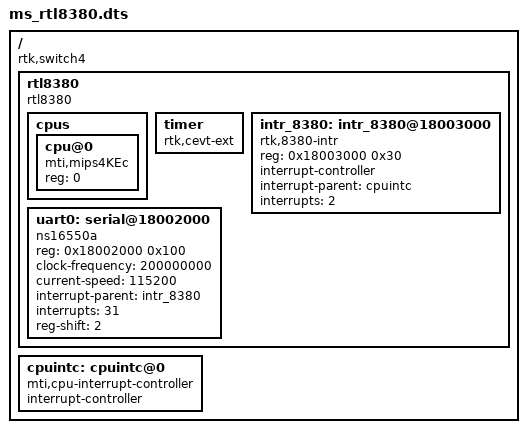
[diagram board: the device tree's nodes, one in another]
/*
 * Realtek Semiconductor Corp.
 *
 * Device Tree Structure
 *
 * RTK Management Switch
 */

/dts-v1/;

#include <dt-bindings/interrupt-controller/mips-gic.h>
#include <dt-bindings/interrupt-controller/irq.h>
#include "../chipDrv/rtl838x/rtk_bsp_rtl8380_intr.h"

/ {
    compatible = "rtk,switch4";
    #address-cells = <1>;
    #size-cells = <1>;

    rtl8380 {
        compatible = "rtl8380", "simple-bus";
        #address-cells = <1>;
        #size-cells = <1>;
        ranges;

        cpus {
            #address-cells = <1>;
            #size-cells = <0>;

            cpu@0 {
                compatible = "mti,mips4KEc";
                device_type = "cpu";
                reg = <0>;
            };
        };

        timer {
            compatible = "rtk,cevt-ext";
        };

        intr_8380: intr_8380@18003000 {
            compatible = "rtk,8380-intr";
            reg = <0x18003000 0x30>;
            interrupt-controller;
            #interrupt-cells = <1>;
            interrupt-parent = <&cpuintc>;
            interrupts = <2>;
        };    
       
        uart0: serial@18002000 {
            compatible = "ns16550a";
            reg = <0x18002000 0x100>;
            clock-frequency = <200000000>;
	    current-speed = <115200>;	
            interrupt-parent = <&intr_8380>;
            interrupts = <31>;
            reg-shift = <2>;
        };        

    };
    
    cpuintc: cpuintc@0 {
        #address-cells = <0>;
        #interrupt-cells = <1>;
        interrupt-controller;
        compatible = "mti,cpu-interrupt-controller";
    };

};
